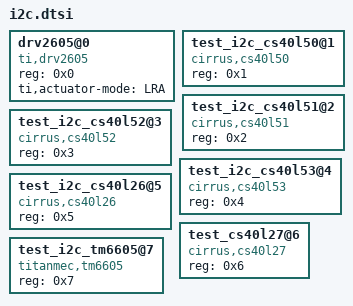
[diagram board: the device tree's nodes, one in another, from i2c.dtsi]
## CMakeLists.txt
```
# Copyright (c) 2024 Cirrus Logic, Inc.
# SPDX-License-Identifier: Apache-2.0

cmake_minimum_required(VERSION 3.28.0)
find_package(Zephyr REQUIRED HINTS $ENV{ZEPHYR_BASE})
project(build_all)

target_sources(app PRIVATE src/main.c)
```

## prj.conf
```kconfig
CONFIG_GPIO=y
CONFIG_HAPTICS=y
```

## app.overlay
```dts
/*
 * Copyright (c) 2024 Cirrus Logic, Inc.
 * SPDX-License-Identifier: Apache-2.0
 */

#include <zephyr/dt-bindings/i2c/i2c.h>

/ {
	test {
		#address-cells = <1>;
		#size-cells = <1>;

		test_i2c: i2c@11112222 {
			compatible = "vnd,i2c";
			reg = <0x11112222 0x1000>;
			#address-cells = <1>;
			#size-cells = <0>;
			clock-frequency = <I2C_BITRATE_STANDARD>;
			status = "okay";

#include "i2c.dtsi"
		};

		test_spi: spi@33334444 {
			compatible = "vnd,spi";
			reg = <0x33334444 0x1000>;
			#address-cells = <1>;
			#size-cells = <0>;
			clock-frequency = <2000000>;

			/* one entry for every devices at spi.dtsi */
			cs-gpios = <&test_gpio 0 0>,
				   <&test_gpio 0 0>,
				   <&test_gpio 0 0>,
				   <&test_gpio 0 0>,
				   <&test_gpio 0 0>,
				   <&test_gpio 0 0>;
			status = "okay";

#include "spi.dtsi"
		};

		test_gpio: gpio@deadbeef {
			compatible = "vnd,gpio";
			reg = <0xdeadbeef 0x1000>;
			gpio-controller;
			#gpio-cells = <0x2>;
			status = "okay";
		};
	};
};
```

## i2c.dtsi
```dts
/*
 * Copyright (c) 2024 Cirrus Logic, Inc.
 * SPDX-License-Identifier: Apache-2.0
 */

/****************************************
 * PLEASE KEEP REG ADDRESSES SEQUENTIAL *
 **************************************
 */

drv2605@0 {
	compatible = "ti,drv2605";
	reg = <0x0>;

	ti,actuator-mode = "LRA";
	status = "okay";
};

test_i2c_cs40l50@1 {
	compatible = "cirrus,cs40l50";
	reg = <0x1>;
	status = "okay";
};

test_i2c_cs40l51@2 {
	compatible = "cirrus,cs40l51";
	reg = <0x2>;
	status = "okay";
};

test_i2c_cs40l52@3 {
	compatible = "cirrus,cs40l52";
	reg = <0x3>;
	status = "okay";
};

test_i2c_cs40l53@4 {
	compatible = "cirrus,cs40l53";
	reg = <0x4>;
	status = "okay";
};

test_i2c_cs40l26@5 {
	compatible = "cirrus,cs40l26";
	reg = <0x5>;
	status = "okay";
};

test_cs40l27@6 {
	compatible = "cirrus,cs40l27";
	reg = <0x6>;
	status = "okay";
};

test_i2c_tm6605@7 {
	compatible = "titanmec,tm6605";
	reg = <0x7>;
	status = "okay";
};
```

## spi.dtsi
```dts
/*
 * Copyright (c) 2026 Cirrus Logic, Inc.
 * SPDX-License-Identifier: Apache-2.0
 */

test_spi_cs40l50@0 {
	compatible = "cirrus,cs40l50";
	reg = <0x0>;
	spi-max-frequency = <5000000>;
	status = "okay";
};

test_spi_cs40l51@1 {
	compatible = "cirrus,cs40l51";
	reg = <0x1>;
	spi-max-frequency = <5000000>;
	status = "okay";
};

test_spi_cs40l52@2 {
	compatible = "cirrus,cs40l52";
	reg = <0x2>;
	spi-max-frequency = <5000000>;
	status = "okay";
};

test_spi_cs40l53@3 {
	compatible = "cirrus,cs40l53";
	reg = <0x3>;
	spi-max-frequency = <5000000>;
	status = "okay";
};

test_spi_cs40l26@4 {
	compatible = "cirrus,cs40l26";
	reg = <0x4>;
	spi-max-frequency = <5000000>;
	status = "okay";
};

test_spi_cs40l27@5 {
	compatible = "cirrus,cs40l27";
	reg = <0x5>;
	spi-max-frequency = <5000000>;
	status = "okay";
};
```

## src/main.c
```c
/*
 * Copyright (c) 2024 Cirrus Logic, Inc.
 * SPDX-License-Identifier: Apache-2.0
 */

int main(void)
{
	return 0;
}
```
